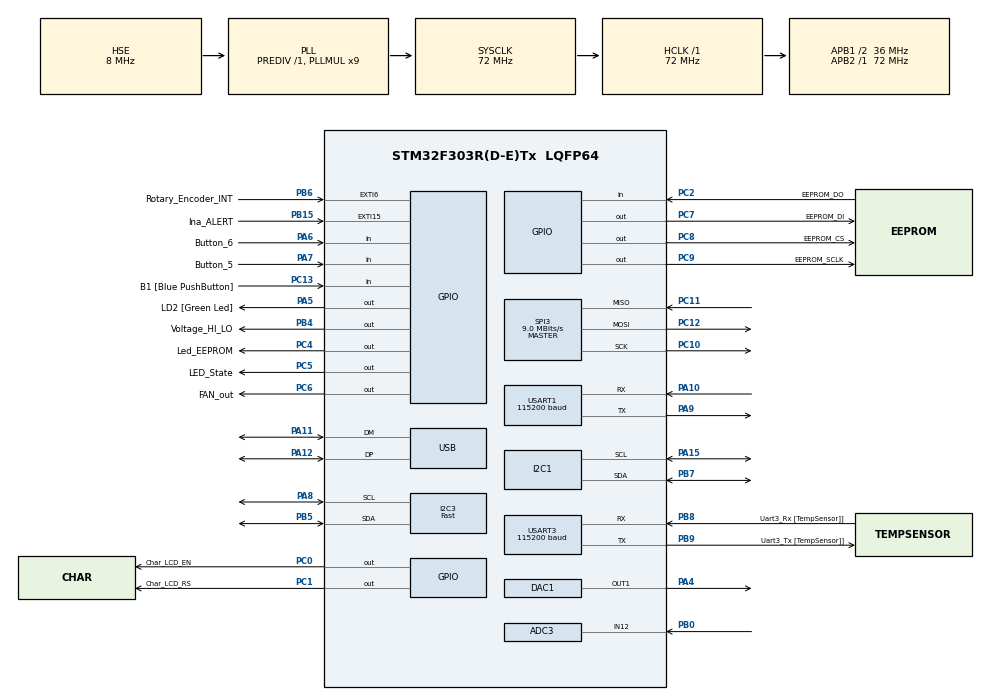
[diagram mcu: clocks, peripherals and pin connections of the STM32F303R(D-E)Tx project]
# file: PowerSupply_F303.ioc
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ADC3.Channel-1\#ChannelRegularConversion=ADC_CHANNEL_12
ADC3.Channel-2\#ChannelRegularConversion=ADC_CHANNEL_12
ADC3.ClockPrescaler=ADC_CLOCK_SYNC_PCLK_DIV1
ADC3.ContinuousConvMode=DISABLE
ADC3.DMAContinuousRequests=DISABLE
ADC3.DataAlign=ADC_DATAALIGN_RIGHT
ADC3.DiscontinuousConvMode=DISABLE
ADC3.EOCSelection=ADC_EOC_SEQ_CONV
ADC3.EnableAnalogWatchDog1=false
ADC3.EnableAnalogWatchDog2=false
ADC3.EnableAnalogWatchDog3=false
ADC3.EnableInjectedConversion=DISABLE
ADC3.EnableRegularConversion=ENABLE
ADC3.ExternalTrigConv=ADC_SOFTWARE_START
ADC3.ExternalTrigConvEdge=ADC_EXTERNALTRIGCONVEDGE_NONE
ADC3.LowPowerAutoWait=DISABLE
ADC3.NbrOfConversion=2
ADC3.NbrOfConversionFlag=1
ADC3.Offset-1\#ChannelRegularConversion=0
ADC3.Offset-2\#ChannelRegularConversion=0
ADC3.OffsetNumber-1\#ChannelRegularConversion=ADC_OFFSET_NONE
ADC3.OffsetNumber-2\#ChannelRegularConversion=ADC_OFFSET_NONE
ADC3.Overrun=ADC_OVR_DATA_OVERWRITTEN
ADC3.Rank-1\#ChannelRegularConversion=1
ADC3.Rank-2\#ChannelRegularConversion=2
ADC3.Resolution=ADC_RESOLUTION_12B
ADC3.SamplingTime-1\#ChannelRegularConversion=ADC_SAMPLETIME_601CYCLES_5
ADC3.SamplingTime-2\#ChannelRegularConversion=ADC_SAMPLETIME_601CYCLES_5
ADC3.ScanConvMode=ADC_SCAN_ENABLE
ADC3.master=1
CRC.InputDataFormat=CRC_INPUTDATA_FORMAT_WORDS
DAC1.DAC_OutputBuffer=DAC_OUTPUTBUFFER_DISABLE
Dma.ADC3.2.Direction=DMA_PERIPH_TO_MEMORY
Dma.ADC3.2.Instance=DMA2_Channel5
Dma.ADC3.2.MemDataAlignment=DMA_MDATAALIGN_HALFWORD
Dma.ADC3.2.MemInc=DMA_MINC_ENABLE
Dma.ADC3.2.Mode=DMA_NORMAL
Dma.ADC3.2.PeriphDataAlignment=DMA_PDATAALIGN_HALFWORD
Dma.ADC3.2.PeriphInc=DMA_PINC_DISABLE
Dma.ADC3.2.Priority=DMA_PRIORITY_LOW
Dma.Request0=USART1_RX
Dma.Request1=USART1_TX
Dma.Request2=ADC3
Dma.USART1_RX.0.Direction=DMA_PERIPH_TO_MEMORY
Dma.USART1_RX.0.Instance=DMA1_Channel5
Dma.USART1_RX.0.MemDataAlignment=DMA_MDATAALIGN_BYTE
Dma.USART1_RX.0.MemInc=DMA_MINC_ENABLE
Dma.USART1_RX.0.Mode=DMA_CIRCULAR
Dma.USART1_RX.0.PeriphDataAlignment=DMA_PDATAALIGN_BYTE
Dma.USART1_RX.0.PeriphInc=DMA_PINC_DISABLE
Dma.USART1_RX.0.Priority=DMA_PRIORITY_HIGH
Dma.USART1_TX.1.Direction=DMA_MEMORY_TO_PERIPH
Dma.USART1_TX.1.Instance=DMA1_Channel4
Dma.USART1_TX.1.MemDataAlignment=DMA_MDATAALIGN_BYTE
Dma.USART1_TX.1.MemInc=DMA_MINC_ENABLE
Dma.USART1_TX.1.Mode=DMA_NORMAL
Dma.USART1_TX.1.PeriphDataAlignment=DMA_PDATAALIGN_BYTE
Dma.USART1_TX.1.PeriphInc=DMA_PINC_DISABLE
Dma.USART1_TX.1.Priority=DMA_PRIORITY_LOW
FREERTOS.CountingSemaphores01=EncdTskDataSem,3,Static,EncdTskDataSemControlBlock;CtrTskDataSem,3,Static,CtrTskDataSemControlBlock;ThetaTskDataSem,3,Static,ThetaTskDataSemControlBlock
FREERTOS.HEAP_NUMBER=5
FREERTOS.Tasks01=displayNMenus,16,128,StrtDisplayNMenus,As weak,NULL,Static,displayNMenuBuffer,displayNMenuBlock;measureNControl,48,128,StrtMeasureNControl,As external,NULL,Static,measureAndContrBuffer,measureAndContrControlBlock;encoderNButtons,24,256,StrtEncoderNButtons,As external,NULL,Static,encoderNButtonsBuffer,encoderNButtonsControlBlock
FREERTOS.configTICK_RATE_HZ=1000
I2C3.I2C_Speed_Mode=I2C_Fast
I2C3.Timing=0x0000020B
Mcu.Family=STM32F3
Mcu.Name=STM32F303R(D-E)Tx
Mcu.Package=LQFP64
NVIC.DMA1_Channel4_IRQn=true\:5\:0\:false\:false\:true\:true\:true\:true
NVIC.DMA1_Channel5_IRQn=true\:5\:0\:false\:false\:true\:true\:true\:true
NVIC.DMA2_Channel5_IRQn=true\:5\:0\:false\:false\:true\:true\:false\:true
NVIC.EXTI15_10_IRQn=true\:5\:0\:false\:false\:true\:true\:true\:true
NVIC.EXTI9_5_IRQn=true\:5\:0\:false\:false\:true\:true\:true\:true
NVIC.I2C3_ER_IRQn=true\:5\:0\:false\:false\:true\:false\:true\:true
NVIC.I2C3_EV_IRQn=true\:5\:0\:false\:false\:true\:false\:true\:true
NVIC.PriorityGroup=NVIC_PRIORITYGROUP_4
NVIC.SPI3_IRQn=true\:5\:0\:false\:false\:true\:true\:true\:true
NVIC.TIM1_UP_TIM16_IRQn=true\:0\:0\:false\:false\:true\:false\:false\:true
NVIC.TimeBase=TIM1_UP_TIM16_IRQn
NVIC.TimeBaseIP=TIM1
NVIC.USART1_IRQn=true\:5\:0\:false\:false\:true\:true\:true\:true
NVIC.USART3_IRQn=true\:5\:0\:false\:false\:true\:true\:true\:true
NVIC.USB_LP_CAN_RX0_IRQn=true\:5\:0\:false\:false\:true\:true\:false\:true
PA10.Mode=Asynchronous
PA10.Signal=USART1_RX
PA11.Mode=Device
PA11.Signal=USB_DM
PA12.Mode=Device
PA12.Signal=USB_DP
PA13.GPIO_Label=TMS
PA13.Mode=Serial_Wire
PA13.Signal=SYS_JTMS-SWDIO
PA14.GPIO_Label=TCK
PA14.Mode=Serial_Wire
PA14.Signal=SYS_JTCK-SWCLK
PA15.Mode=I2C
PA15.Signal=I2C1_SCL
PA2.GPIO_Label=USART_TX
PA2.GPIO_Mode=GPIO_MODE_AF_PP
PA2.GPIO_PuPd=GPIO_NOPULL
PA2.GPIO_Speed=GPIO_SPEED_FREQ_LOW
PA2.Signal=USART2_TX
PA3.GPIO_Label=USART_RX
PA3.GPIO_Mode=GPIO_MODE_AF_PP
PA3.GPIO_PuPd=GPIO_NOPULL
PA3.GPIO_Speed=GPIO_SPEED_FREQ_LOW
PA3.Signal=USART2_RX
PA4.Signal=COMP_DAC11_group
PA5.GPIO_Label=LD2 [Green Led]
PA5.GPIO_Mode=GPIO_MODE_OUTPUT_PP
PA5.GPIO_PuPd=GPIO_NOPULL
PA5.GPIO_Speed=GPIO_SPEED_FREQ_HIGH
PA5.Signal=GPIO_Output
PA6.GPIO_Label=Button_6
PA6.GPIO_PuPd=GPIO_PULLUP
PA6.Signal=GPIO_Input
PA7.GPIO_Label=Button_5
PA7.GPIO_PuPd=GPIO_PULLUP
PA7.Signal=GPIO_Input
PA8.Mode=I2C
PA8.Signal=I2C3_SCL
PA9.Mode=Asynchronous
PA9.Signal=USART1_TX
PB0.Mode=IN12-Single-Ended
PB0.Signal=ADC3_IN12
PB15.GPIO_Label=Ina_ALERT
PB15.GPIO_ModeDefaultEXTI=GPIO_MODE_IT_FALLING
PB15.GPIO_PuPd=GPIO_PULLUP
PB15.Signal=GPXTI15
PB3.GPIO_Label=JLink_SWO
PB3.Signal=SYS_JTDO-TRACESWO
PB4.GPIO_Label=Voltage_HI_LO
PB4.Signal=GPIO_Output
PB5.Mode=I2C
PB5.Signal=I2C3_SDA
PB6.GPIO_Label=Rotary_Encoder_INT
PB6.GPIO_ModeDefaultEXTI=GPIO_MODE_IT_FALLING
PB6.GPIO_PuPd=GPIO_PULLUP
PB6.Signal=GPXTI6
PB7.Mode=I2C
PB7.Signal=I2C1_SDA
PB8.GPIO_Label=Uart3_Rx [TempSensor]]
PB8.Mode=Asynchronous
PB8.Signal=USART3_RX
PB9.GPIO_Label=Uart3_Tx [TempSensor]]
PB9.Mode=Asynchronous
PB9.Signal=USART3_TX
PC0.GPIO_Label=Char_LCD_EN
PC0.GPIO_Speed=GPIO_SPEED_FREQ_HIGH
PC0.Signal=GPIO_Output
PC1.GPIO_Label=Char_LCD_RS
PC1.GPIO_Speed=GPIO_SPEED_FREQ_HIGH
PC1.Signal=GPIO_Output
PC10.Mode=Full_Duplex_Master
PC10.Signal=SPI3_SCK
PC11.Mode=Full_Duplex_Master
PC11.Signal=SPI3_MISO
PC12.Mode=Full_Duplex_Master
PC12.Signal=SPI3_MOSI
PC13.GPIO_Label=B1 [Blue PushButton]
PC13.Signal=GPIO_Input
PC14-OSC32_IN.Mode=LSE-External-Oscillator
PC14-OSC32_IN.Signal=RCC_OSC32_IN
PC15-OSC32_OUT.Mode=LSE-External-Oscillator
PC15-OSC32_OUT.Signal=RCC_OSC32_OUT
PC2.GPIO_Label=EEPROM_DO
PC2.Signal=GPIO_Input
PC4.GPIO_Label=Led_EEPROM
PC4.Signal=GPIO_Output
PC5.GPIO_Label=LED_State
PC5.Signal=GPIO_Output
PC6.GPIO_Label=FAN_out
PC6.Signal=GPIO_Output
PC7.GPIO_Label=EEPROM_DI
PC7.Signal=GPIO_Output
PC8.GPIO_Label=EEPROM_CS
PC8.GPIO_Speed=GPIO_SPEED_FREQ_HIGH
PC8.Signal=GPIO_Output
PC9.GPIO_Label=EEPROM_SCLK
PC9.Signal=GPIO_Output
PF0-OSC_IN.Mode=HSE-External-Oscillator
PF0-OSC_IN.Signal=RCC_OSC_IN
PF1-OSC_OUT.Mode=HSE-External-Oscillator
PF1-OSC_OUT.Signal=RCC_OSC_OUT
ProjectManager.HeapSize=0x200
ProjectManager.StackSize=0x400
ProjectManager.TargetToolchain=STM32CubeIDE
RCC.AHBFreq_Value=72000000
RCC.APB1CLKDivider=RCC_HCLK_DIV2
RCC.APB1Freq_Value=36000000
RCC.APB1TimFreq_Value=72000000
RCC.APB2Freq_Value=72000000
RCC.APB2TimFreq_Value=72000000
RCC.CortexFreq_Value=72000000
RCC.HCLKFreq_Value=72000000
RCC.HSE_VALUE=8000000
RCC.HSI_VALUE=8000000
RCC.PLLM=8
RCC.PLLMUL=RCC_PLL_MUL9
RCC.PLLN=336
RCC.PLLP=RCC_PLLP_DIV4
RCC.PLLQ=7
RCC.PRESCALERUSB=RCC_USBCLKSOURCE_PLL_DIV1_5
RCC.RCC_MCODiv=RCC_MCODIV_16
RCC.RCC_MCOMult_Clock_Source_FROM_PLLMUL=RCC_MCO1SOURCE_PLLCLK_DIV2
RCC.RCC_MCOSource=RCC_MCO1SOURCE_PLLCLK_DIV2
RCC.RCC_PLLsource_Clock_Source_FROM_HSE=RCC_HSE_PREDIV_DIV2
RCC.SYSCLKFreq_VALUE=72000000
RCC.SYSCLKSourceVirtual=RCC_SYSCLKSOURCE_PLLCLK
RCC.USBFreq_Value=48000000
SH.COMP_DAC11_group.0=DAC1_OUT1,DAC_OUT1
SPI3.BaudRatePrescaler=SPI_BAUDRATEPRESCALER_4
SPI3.CalculateBaudRate=9.0 MBits/s
SPI3.DataSize=SPI_DATASIZE_8BIT
SPI3.Direction=SPI_DIRECTION_2LINES
SPI3.FirstBit=SPI_FIRSTBIT_MSB
SPI3.Mode=SPI_MODE_MASTER
SPI3.NSSPMode=SPI_NSS_PULSE_DISABLE
SPI3.VirtualType=VM_MASTER
USART1.BaudRate=115200
USART1.VirtualMode-Asynchronous=VM_ASYNC
USART1.WordLength=WORDLENGTH_8B
USART3.BaudRate=115200
USART3.VirtualMode-Asynchronous=VM_ASYNC
USB_DEVICE.APP_RX_DATA_SIZE=128
USB_DEVICE.APP_TX_DATA_SIZE=128
USB_DEVICE.CLASS_NAME_FS=CDC
USB_DEVICE.VirtualMode=Cdc
USB_DEVICE.VirtualModeFS=Cdc_FS
VP_CRC_VS_CRC.Mode=CRC_Activate
VP_FREERTOS_VS_CMSIS_V2.Mode=CMSIS_V2
VP_SYS_VS_tim1.Mode=TIM1
VP_USB_DEVICE_VS_USB_DEVICE_CDC_FS.Mode=CDC_FS
board=NUCLEO-F303RE

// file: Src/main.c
/* USER CODE BEGIN Header */
/**
  ******************************************************************************
  * @file           : main.c
  * @brief          : Main program body
  ******************************************************************************
  * @attention
  *
  * <h2><center>&copy; Copyright (c) 2020 STMicroelectronics.
  * All rights reserved.</center></h2>
  *
  * This software component is licensed by ST under BSD 3-Clause license,
  * the "License"; You may not use this file except in compliance with the
  * License. You may obtain a copy of the License at:
  *                        opensource.org/licenses/BSD-3-Clause
  *
  ******************************************************************************
  */
/* USER CODE END Header */
#include "main.h"
#include "cmsis_os.h"
#include "usb_device.h"

/* USER CODE BEGIN Includes */

#include <Instances/Common.h>

/* USER CODE END Includes */

typedef StaticTask_t osStaticThreadDef_t;
typedef StaticSemaphore_t osStaticSemaphoreDef_t;

ADC_HandleTypeDef hadc3;
DMA_HandleTypeDef hdma_adc3;

CRC_HandleTypeDef hcrc;

DAC_HandleTypeDef hdac1;

I2C_HandleTypeDef hi2c1;
I2C_HandleTypeDef hi2c3;

SPI_HandleTypeDef hspi3;

UART_HandleTypeDef huart1;
UART_HandleTypeDef huart3;
DMA_HandleTypeDef hdma_usart1_rx;
DMA_HandleTypeDef hdma_usart1_tx;

/* Definitions for displayNMenus */
osThreadId_t displayNMenusHandle;
uint32_t displayNMenuBuffer[ 128 ];
osStaticThreadDef_t displayNMenuBlock;
const osThreadAttr_t displayNMenus_attributes = {
  .name = "displayNMenus",
  .stack_mem = &displayNMenuBuffer[0],
  .stack_size = sizeof(displayNMenuBuffer),
  .cb_mem = &displayNMenuBlock,
  .cb_size = sizeof(displayNMenuBlock),
  .priority = (osPriority_t) osPriorityBelowNormal,
};
/* Definitions for measureNControl */
osThreadId_t measureNControlHandle;
uint32_t measureAndContrBuffer[ 128 ];
osStaticThreadDef_t measureAndContrControlBlock;
const osThreadAttr_t measureNControl_attributes = {
  .name = "measureNControl",
  .stack_mem = &measureAndContrBuffer[0],
  .stack_size = sizeof(measureAndContrBuffer),
  .cb_mem = &measureAndContrControlBlock,
  .cb_size = sizeof(measureAndContrControlBlock),
  .priority = (osPriority_t) osPriorityRealtime,
};
/* Definitions for encoderNButtons */
osThreadId_t encoderNButtonsHandle;
uint32_t encoderNButtonsBuffer[ 256 ];
osStaticThreadDef_t encoderNButtonsControlBlock;
const osThreadAttr_t encoderNButtons_attributes = {
  .name = "encoderNButtons",
  .stack_mem = &encoderNButtonsBuffer[0],
  .stack_size = sizeof(encoderNButtonsBuffer),
  .cb_mem = &encoderNButtonsControlBlock,
  .cb_size = sizeof(encoderNButtonsControlBlock),
  .priority = (osPriority_t) osPriorityNormal,
};
/* Definitions for EncdTskDataSem */
osSemaphoreId_t EncdTskDataSemHandle;
osStaticSemaphoreDef_t EncdTskDataSemControlBlock;
const osSemaphoreAttr_t EncdTskDataSem_attributes = {
  .name = "EncdTskDataSem",
  .cb_mem = &EncdTskDataSemControlBlock,
  .cb_size = sizeof(EncdTskDataSemControlBlock),
};
/* Definitions for CtrTskDataSem */
osSemaphoreId_t CtrTskDataSemHandle;
osStaticSemaphoreDef_t CtrTskDataSemControlBlock;
const osSemaphoreAttr_t CtrTskDataSem_attributes = {
  .name = "CtrTskDataSem",
  .cb_mem = &CtrTskDataSemControlBlock,
  .cb_size = sizeof(CtrTskDataSemControlBlock),
};
/* Definitions for ThetaTskDataSem */
osSemaphoreId_t ThetaTskDataSemHandle;
osStaticSemaphoreDef_t ThetaTskDataSemControlBlock;
const osSemaphoreAttr_t ThetaTskDataSem_attributes = {
  .name = "ThetaTskDataSem",
  .cb_mem = &ThetaTskDataSemControlBlock,
  .cb_size = sizeof(ThetaTskDataSemControlBlock),
};

void SystemClock_Config(void);
static void MX_GPIO_Init(void);
static void MX_DMA_Init(void);
static void MX_ADC3_Init(void);
static void MX_DAC1_Init(void);
static void MX_I2C1_Init(void);
static void MX_SPI3_Init(void);
static void MX_USART1_UART_Init(void);
static void MX_I2C3_Init(void);
static void MX_USART3_UART_Init(void);
static void MX_CRC_Init(void);
void StrtDisplayNMenus(void *argument);
extern void StrtMeasureNControl(void *argument);
extern void StrtEncoderNButtons(void *argument);

/* USER CODE BEGIN 0 */

UART_HandleTypeDef* get_huart1(void) 	{ return &huart1; 	}
//UART_HandleTypeDef* get_huart2(void) 	{ return &huart2; 	}
UART_HandleTypeDef* get_huart3(void) 	{ return &huart3; 	}
SPI_HandleTypeDef* 	get_hspi3 (void)  	{ return &hspi3;  	}
I2C_HandleTypeDef* 	get_hi2c1 (void) 	{ return &hi2c1;  	}
I2C_HandleTypeDef* 	get_hi2c3 (void) 	{ return &hi2c3;  	}
ADC_HandleTypeDef*  get_hadc3 (void)  	{ return &hadc3;  	}
DAC_HandleTypeDef*  get_hdac1(void)   	{ return &hdac1;  	}
CRC_HandleTypeDef* 	get_hcrc(void)		{ return &hcrc;		}
/* USER CODE END 0 */

int main(void)
{

  /* MCU Configuration--------------------------------------------------------*/

  /* Reset of all peripherals, Initializes the Flash interface and the Systick. */
  HAL_Init();

  /* Configure the system clock */
  SystemClock_Config();

  /* Initialize all configured peripherals */
  MX_GPIO_Init();
  MX_DMA_Init();
  MX_ADC3_Init();
  MX_DAC1_Init();
  MX_I2C1_Init();
  MX_SPI3_Init();
  MX_USART1_UART_Init();
  MX_I2C3_Init();
  MX_USART3_UART_Init();
  MX_CRC_Init();
  /* USER CODE BEGIN 2 */

  common_init();

  /* USER CODE END 2 */

  /* Init scheduler */
  osKernelInitialize();

  /* Create the semaphores(s) */
  /* creation of EncdTskDataSem */
  EncdTskDataSemHandle = osSemaphoreNew(3, 3, &EncdTskDataSem_attributes);

  /* creation of CtrTskDataSem */
  CtrTskDataSemHandle = osSemaphoreNew(3, 3, &CtrTskDataSem_attributes);

  /* creation of ThetaTskDataSem */
  ThetaTskDataSemHandle = osSemaphoreNew(3, 3, &ThetaTskDataSem_attributes);

  /* Create the thread(s) */
  /* creation of displayNMenus */
  displayNMenusHandle = osThreadNew(StrtDisplayNMenus, NULL, &displayNMenus_attributes);

  /* creation of measureNControl */
  measureNControlHandle = osThreadNew(StrtMeasureNControl, NULL, &measureNControl_attributes);

  /* creation of encoderNButtons */
  encoderNButtonsHandle = osThreadNew(StrtEncoderNButtons, NULL, &encoderNButtons_attributes);

  /* Start scheduler */
  osKernelStart();

  /* We should never get here as control is now taken by the scheduler */
  /* Infinite loop */
  /* USER CODE BEGIN WHILE */
  while (1)
  {

  	//mainCycle();

    /* USER CODE END WHILE */

  }
}

void SystemClock_Config(void)
{
  RCC_OscInitTypeDef RCC_OscInitStruct = {0};
  RCC_ClkInitTypeDef RCC_ClkInitStruct = {0};
  RCC_PeriphCLKInitTypeDef PeriphClkInit = {0};

  /** Initializes the RCC Oscillators according to the specified parameters
  * in the RCC_OscInitTypeDef structure.
  */
  RCC_OscInitStruct.OscillatorType = RCC_OSCILLATORTYPE_HSI|RCC_OSCILLATORTYPE_HSE;
  RCC_OscInitStruct.HSEState = RCC_HSE_ON;
  RCC_OscInitStruct.HSIState = RCC_HSI_ON;
  RCC_OscInitStruct.HSICalibrationValue = RCC_HSICALIBRATION_DEFAULT;
  RCC_OscInitStruct.PLL.PLLState = RCC_PLL_ON;
  RCC_OscInitStruct.PLL.PLLSource = RCC_PLLSOURCE_HSE;
  RCC_OscInitStruct.PLL.PLLMUL = RCC_PLL_MUL9;
  RCC_OscInitStruct.PLL.PREDIV = RCC_PREDIV_DIV1;
  if (HAL_RCC_OscConfig(&RCC_OscInitStruct) != HAL_OK)
  {
    Error_Handler();
  }
  /** Initializes the CPU, AHB and APB buses clocks
  */
  RCC_ClkInitStruct.ClockType = RCC_CLOCKTYPE_HCLK|RCC_CLOCKTYPE_SYSCLK
                              |RCC_CLOCKTYPE_PCLK1|RCC_CLOCKTYPE_PCLK2;
  RCC_ClkInitStruct.SYSCLKSource = RCC_SYSCLKSOURCE_PLLCLK;
  RCC_ClkInitStruct.AHBCLKDivider = RCC_SYSCLK_DIV1;
  RCC_ClkInitStruct.APB1CLKDivider = RCC_HCLK_DIV2;
  RCC_ClkInitStruct.APB2CLKDivider = RCC_HCLK_DIV1;

  if (HAL_RCC_ClockConfig(&RCC_ClkInitStruct, FLASH_LATENCY_2) != HAL_OK)
  {
    Error_Handler();
  }
  PeriphClkInit.PeriphClockSelection = RCC_PERIPHCLK_USB|RCC_PERIPHCLK_USART1
                              |RCC_PERIPHCLK_USART3|RCC_PERIPHCLK_I2C1
                              |RCC_PERIPHCLK_I2C3;
  PeriphClkInit.Usart1ClockSelection = RCC_USART1CLKSOURCE_PCLK2;
  PeriphClkInit.Usart3ClockSelection = RCC_USART3CLKSOURCE_PCLK1;
  PeriphClkInit.I2c1ClockSelection = RCC_I2C1CLKSOURCE_HSI;
  PeriphClkInit.I2c3ClockSelection = RCC_I2C3CLKSOURCE_HSI;
  PeriphClkInit.USBClockSelection = RCC_USBCLKSOURCE_PLL_DIV1_5;
  if (HAL_RCCEx_PeriphCLKConfig(&PeriphClkInit) != HAL_OK)
  {
    Error_Handler();
  }
}

static void MX_ADC3_Init(void)
{

  ADC_MultiModeTypeDef multimode = {0};
  ADC_ChannelConfTypeDef sConfig = {0};

  /** Common config
  */
  hadc3.Instance = ADC3;
  hadc3.Init.ClockPrescaler = ADC_CLOCK_SYNC_PCLK_DIV1;
  hadc3.Init.Resolution = ADC_RESOLUTION_12B;
  hadc3.Init.ScanConvMode = ADC_SCAN_ENABLE;
  hadc3.Init.ContinuousConvMode = DISABLE;
  hadc3.Init.DiscontinuousConvMode = DISABLE;
  hadc3.Init.ExternalTrigConvEdge = ADC_EXTERNALTRIGCONVEDGE_NONE;
  hadc3.Init.ExternalTrigConv = ADC_SOFTWARE_START;
  hadc3.Init.DataAlign = ADC_DATAALIGN_RIGHT;
  hadc3.Init.NbrOfConversion = 2;
  hadc3.Init.DMAContinuousRequests = DISABLE;
  hadc3.Init.EOCSelection = ADC_EOC_SEQ_CONV;
  hadc3.Init.LowPowerAutoWait = DISABLE;
  hadc3.Init.Overrun = ADC_OVR_DATA_OVERWRITTEN;
  if (HAL_ADC_Init(&hadc3) != HAL_OK)
  {
    Error_Handler();
  }
  /** Configure the ADC multi-mode
  */
  multimode.Mode = ADC_MODE_INDEPENDENT;
  if (HAL_ADCEx_MultiModeConfigChannel(&hadc3, &multimode) != HAL_OK)
  {
    Error_Handler();
  }
  /** Configure Regular Channel
  */
  sConfig.Channel = ADC_CHANNEL_12;
  sConfig.Rank = ADC_REGULAR_RANK_1;
  sConfig.SingleDiff = ADC_SINGLE_ENDED;
  sConfig.SamplingTime = ADC_SAMPLETIME_601CYCLES_5;
  sConfig.OffsetNumber = ADC_OFFSET_NONE;
  sConfig.Offset = 0;
  if (HAL_ADC_ConfigChannel(&hadc3, &sConfig) != HAL_OK)
  {
    Error_Handler();
  }
  /** Configure Regular Channel
  */
  sConfig.Rank = ADC_REGULAR_RANK_2;
  if (HAL_ADC_ConfigChannel(&hadc3, &sConfig) != HAL_OK)
  {
    Error_Handler();
  }

}

static void MX_CRC_Init(void)
{

  hcrc.Instance = CRC;
  hcrc.Init.DefaultPolynomialUse = DEFAULT_POLYNOMIAL_ENABLE;
  hcrc.Init.DefaultInitValueUse = DEFAULT_INIT_VALUE_ENABLE;
  hcrc.Init.InputDataInversionMode = CRC_INPUTDATA_INVERSION_NONE;
  hcrc.Init.OutputDataInversionMode = CRC_OUTPUTDATA_INVERSION_DISABLE;
  hcrc.InputDataFormat = CRC_INPUTDATA_FORMAT_WORDS;
  if (HAL_CRC_Init(&hcrc) != HAL_OK)
  {
    Error_Handler();
  }

}

static void MX_DAC1_Init(void)
{

  DAC_ChannelConfTypeDef sConfig = {0};

  /** DAC Initialization
  */
  hdac1.Instance = DAC1;
  if (HAL_DAC_Init(&hdac1) != HAL_OK)
  {
    Error_Handler();
  }
  /** DAC channel OUT1 config
  */
  sConfig.DAC_Trigger = DAC_TRIGGER_NONE;
  sConfig.DAC_OutputBuffer = DAC_OUTPUTBUFFER_DISABLE;
  if (HAL_DAC_ConfigChannel(&hdac1, &sConfig, DAC_CHANNEL_1) != HAL_OK)
  {
    Error_Handler();
  }

}

static void MX_I2C1_Init(void)
{

  hi2c1.Instance = I2C1;
  hi2c1.Init.Timing = 0x2000090E;
  hi2c1.Init.OwnAddress1 = 0;
  hi2c1.Init.AddressingMode = I2C_ADDRESSINGMODE_7BIT;
  hi2c1.Init.DualAddressMode = I2C_DUALADDRESS_DISABLE;
  hi2c1.Init.OwnAddress2 = 0;
  hi2c1.Init.OwnAddress2Masks = I2C_OA2_NOMASK;
  hi2c1.Init.GeneralCallMode = I2C_GENERALCALL_DISABLE;
  hi2c1.Init.NoStretchMode = I2C_NOSTRETCH_DISABLE;
  if (HAL_I2C_Init(&hi2c1) != HAL_OK)
  {
    Error_Handler();
  }
  /** Configure Analogue filter
  */
  if (HAL_I2CEx_ConfigAnalogFilter(&hi2c1, I2C_ANALOGFILTER_ENABLE) != HAL_OK)
  {
    Error_Handler();
  }
  /** Configure Digital filter
  */
  if (HAL_I2CEx_ConfigDigitalFilter(&hi2c1, 0) != HAL_OK)
  {
    Error_Handler();
  }

}

static void MX_I2C3_Init(void)
{

  hi2c3.Instance = I2C3;
  hi2c3.Init.Timing = 0x0000020B;
  hi2c3.Init.OwnAddress1 = 0;
  hi2c3.Init.AddressingMode = I2C_ADDRESSINGMODE_7BIT;
  hi2c3.Init.DualAddressMode = I2C_DUALADDRESS_DISABLE;
  hi2c3.Init.OwnAddress2 = 0;
  hi2c3.Init.OwnAddress2Masks = I2C_OA2_NOMASK;
  hi2c3.Init.GeneralCallMode = I2C_GENERALCALL_DISABLE;
  hi2c3.Init.NoStretchMode = I2C_NOSTRETCH_DISABLE;
  if (HAL_I2C_Init(&hi2c3) != HAL_OK)
  {
    Error_Handler();
  }
  /** Configure Analogue filter
  */
  if (HAL_I2CEx_ConfigAnalogFilter(&hi2c3, I2C_ANALOGFILTER_ENABLE) != HAL_OK)
  {
    Error_Handler();
  }
  /** Configure Digital filter
  */
  if (HAL_I2CEx_ConfigDigitalFilter(&hi2c3, 0) != HAL_OK)
  {
    Error_Handler();
  }

}

static void MX_SPI3_Init(void)
{

  /* SPI3 parameter configuration*/
  hspi3.Instance = SPI3;
  hspi3.Init.Mode = SPI_MODE_MASTER;
  hspi3.Init.Direction = SPI_DIRECTION_2LINES;
  hspi3.Init.DataSize = SPI_DATASIZE_8BIT;
  hspi3.Init.CLKPolarity = SPI_POLARITY_LOW;
  hspi3.Init.CLKPhase = SPI_PHASE_1EDGE;
  hspi3.Init.NSS = SPI_NSS_SOFT;
  hspi3.Init.BaudRatePrescaler = SPI_BAUDRATEPRESCALER_4;
  hspi3.Init.FirstBit = SPI_FIRSTBIT_MSB;
  hspi3.Init.TIMode = SPI_TIMODE_DISABLE;
  hspi3.Init.CRCCalculation = SPI_CRCCALCULATION_DISABLE;
  hspi3.Init.CRCPolynomial = 7;
  hspi3.Init.CRCLength = SPI_CRC_LENGTH_DATASIZE;
  hspi3.Init.NSSPMode = SPI_NSS_PULSE_DISABLE;
  if (HAL_SPI_Init(&hspi3) != HAL_OK)
  {
    Error_Handler();
  }

}

static void MX_USART1_UART_Init(void)
{

  huart1.Instance = USART1;
  huart1.Init.BaudRate = 115200;
  huart1.Init.WordLength = UART_WORDLENGTH_8B;
  huart1.Init.StopBits = UART_STOPBITS_1;
  huart1.Init.Parity = UART_PARITY_NONE;
  huart1.Init.Mode = UART_MODE_TX_RX;
  huart1.Init.HwFlowCtl = UART_HWCONTROL_NONE;
  huart1.Init.OverSampling = UART_OVERSAMPLING_16;
  huart1.Init.OneBitSampling = UART_ONE_BIT_SAMPLE_DISABLE;
  huart1.AdvancedInit.AdvFeatureInit = UART_ADVFEATURE_NO_INIT;
  if (HAL_UART_Init(&huart1) != HAL_OK)
  {
    Error_Handler();
  }

}

static void MX_USART3_UART_Init(void)
{

  huart3.Instance = USART3;
  huart3.Init.BaudRate = 115200;
  huart3.Init.WordLength = UART_WORDLENGTH_8B;
  huart3.Init.StopBits = UART_STOPBITS_1;
  huart3.Init.Parity = UART_PARITY_NONE;
  huart3.Init.Mode = UART_MODE_TX_RX;
  huart3.Init.HwFlowCtl = UART_HWCONTROL_NONE;
  huart3.Init.OverSampling = UART_OVERSAMPLING_16;
  huart3.Init.OneBitSampling = UART_ONE_BIT_SAMPLE_DISABLE;
  huart3.AdvancedInit.AdvFeatureInit = UART_ADVFEATURE_NO_INIT;
  if (HAL_UART_Init(&huart3) != HAL_OK)
  {
    Error_Handler();
  }

}

static void MX_DMA_Init(void)
{

  /* DMA controller clock enable */
  __HAL_RCC_DMA1_CLK_ENABLE();
  __HAL_RCC_DMA2_CLK_ENABLE();

  /* DMA interrupt init */
  /* DMA1_Channel4_IRQn interrupt configuration */
  HAL_NVIC_SetPriority(DMA1_Channel4_IRQn, 5, 0);
  HAL_NVIC_EnableIRQ(DMA1_Channel4_IRQn);
  /* DMA1_Channel5_IRQn interrupt configuration */
  HAL_NVIC_SetPriority(DMA1_Channel5_IRQn, 5, 0);
  HAL_NVIC_EnableIRQ(DMA1_Channel5_IRQn);
  /* DMA2_Channel5_IRQn interrupt configuration */
  HAL_NVIC_SetPriority(DMA2_Channel5_IRQn, 5, 0);
  HAL_NVIC_EnableIRQ(DMA2_Channel5_IRQn);

}

static void MX_GPIO_Init(void)
{
  GPIO_InitTypeDef GPIO_InitStruct = {0};

  /* GPIO Ports Clock Enable */
  __HAL_RCC_GPIOC_CLK_ENABLE();
  __HAL_RCC_GPIOF_CLK_ENABLE();
  __HAL_RCC_GPIOA_CLK_ENABLE();
  __HAL_RCC_GPIOB_CLK_ENABLE();

  /*Configure GPIO pin Output Level */
  HAL_GPIO_WritePin(GPIOC, Char_LCD_EN_Pin|Char_LCD_RS_Pin|Led_EEPROM_Pin|LED_State_Pin
                          |FAN_out_Pin|EEPROM_DI_Pin|EEPROM_CS_Pin|EEPROM_SCLK_Pin, GPIO_PIN_RESET);

  /*Configure GPIO pin Output Level */
  HAL_GPIO_WritePin(LD2_GPIO_Port, LD2_Pin, GPIO_PIN_RESET);

  /*Configure GPIO pin Output Level */
  HAL_GPIO_WritePin(Voltage_HI_LO_GPIO_Port, Voltage_HI_LO_Pin, GPIO_PIN_RESET);

  /*Configure GPIO pins : B1_Pin EEPROM_DO_Pin */
  GPIO_InitStruct.Pin = B1_Pin|EEPROM_DO_Pin;
  GPIO_InitStruct.Mode = GPIO_MODE_INPUT;
  GPIO_InitStruct.Pull = GPIO_NOPULL;
  HAL_GPIO_Init(GPIOC, &GPIO_InitStruct);

  /*Configure GPIO pins : Char_LCD_EN_Pin Char_LCD_RS_Pin EEPROM_CS_Pin */
  GPIO_InitStruct.Pin = Char_LCD_EN_Pin|Char_LCD_RS_Pin|EEPROM_CS_Pin;
  GPIO_InitStruct.Mode = GPIO_MODE_OUTPUT_PP;
  GPIO_InitStruct.Pull = GPIO_NOPULL;
  GPIO_InitStruct.Speed = GPIO_SPEED_FREQ_HIGH;
  HAL_GPIO_Init(GPIOC, &GPIO_InitStruct);

  /*Configure GPIO pins : USART_TX_Pin USART_RX_Pin */
  GPIO_InitStruct.Pin = USART_TX_Pin|USART_RX_Pin;
  GPIO_InitStruct.Mode = GPIO_MODE_AF_PP;
  GPIO_InitStruct.Pull = GPIO_NOPULL;
  GPIO_InitStruct.Speed = GPIO_SPEED_FREQ_LOW;
  GPIO_InitStruct.Alternate = GPIO_AF7_USART2;
  HAL_GPIO_Init(GPIOA, &GPIO_InitStruct);

  /*Configure GPIO pin : LD2_Pin */
  GPIO_InitStruct.Pin = LD2_Pin;
  GPIO_InitStruct.Mode = GPIO_MODE_OUTPUT_PP;
  GPIO_InitStruct.Pull = GPIO_NOPULL;
  GPIO_InitStruct.Speed = GPIO_SPEED_FREQ_HIGH;
  HAL_GPIO_Init(LD2_GPIO_Port, &GPIO_InitStruct);

  /*Configure GPIO pins : Button_6_Pin Button_5_Pin */
  GPIO_InitStruct.Pin = Button_6_Pin|Button_5_Pin;
  GPIO_InitStruct.Mode = GPIO_MODE_INPUT;
  GPIO_InitStruct.Pull = GPIO_PULLUP;
  HAL_GPIO_Init(GPIOA, &GPIO_InitStruct);

  /*Configure GPIO pins : Led_EEPROM_Pin LED_State_Pin FAN_out_Pin EEPROM_DI_Pin
                           EEPROM_SCLK_Pin */
  GPIO_InitStruct.Pin = Led_EEPROM_Pin|LED_State_Pin|FAN_out_Pin|EEPROM_DI_Pin
                          |EEPROM_SCLK_Pin;
  GPIO_InitStruct.Mode = GPIO_MODE_OUTPUT_PP;
  GPIO_InitStruct.Pull = GPIO_NOPULL;
  GPIO_InitStruct.Speed = GPIO_SPEED_FREQ_LOW;
  HAL_GPIO_Init(GPIOC, &GPIO_InitStruct);

  /*Configure GPIO pins : Ina_ALERT_Pin Rotary_Encoder_INT_Pin */
  GPIO_InitStruct.Pin = Ina_ALERT_Pin|Rotary_Encoder_INT_Pin;
  GPIO_InitStruct.Mode = GPIO_MODE_IT_FALLING;
  GPIO_InitStruct.Pull = GPIO_PULLUP;
  HAL_GPIO_Init(GPIOB, &GPIO_InitStruct);

  /*Configure GPIO pin : Voltage_HI_LO_Pin */
  GPIO_InitStruct.Pin = Voltage_HI_LO_Pin;
  GPIO_InitStruct.Mode = GPIO_MODE_OUTPUT_PP;
  GPIO_InitStruct.Pull = GPIO_NOPULL;
  GPIO_InitStruct.Speed = GPIO_SPEED_FREQ_LOW;
  HAL_GPIO_Init(Voltage_HI_LO_GPIO_Port, &GPIO_InitStruct);

  /* EXTI interrupt init*/
  HAL_NVIC_SetPriority(EXTI9_5_IRQn, 5, 0);
  HAL_NVIC_EnableIRQ(EXTI9_5_IRQn);

  HAL_NVIC_SetPriority(EXTI15_10_IRQn, 5, 0);
  HAL_NVIC_EnableIRQ(EXTI15_10_IRQn);

}

__weak void StrtDisplayNMenus(void *argument)
{
  /* init code for USB_DEVICE */
  MX_USB_DEVICE_Init();
  for(;;)
  {
    osDelay(1);
  }
}

 /**
  * @brief  Period elapsed callback in non blocking mode
  * @note   This function is called  when TIM1 interrupt took place, inside
  * HAL_TIM_IRQHandler(). It makes a direct call to HAL_IncTick() to increment
  * a global variable "uwTick" used as application time base.
  * @param  htim : TIM handle
  * @retval None
  */
void HAL_TIM_PeriodElapsedCallback(TIM_HandleTypeDef *htim)
{
  if (htim->Instance == TIM1) {
    HAL_IncTick();
  }
}

void Error_Handler(void)
{
}

/************************ (C) COPYRIGHT STMicroelectronics *****END OF FILE****/
